# R7FA2L1AB register map
Vendor: Renesas Electronics Corporation; Series: RA2L1; File version: 1.60.00
CPU: CM23 r1p0, little endian, MPU, no FPU, VTOR, 2 interrupt priority bits, 32 interrupts
Registers are 8-bit, read-write, reset 0x0 unless marked. A register's access mark holds for its fields unless they carry their own. Offsets are from the block's base; [hi:lo] are bit positions; 'fields as' and 'values as' point back to an identical list.

## POEG — Port Output Enable Module for GPT
Base 0x40042000
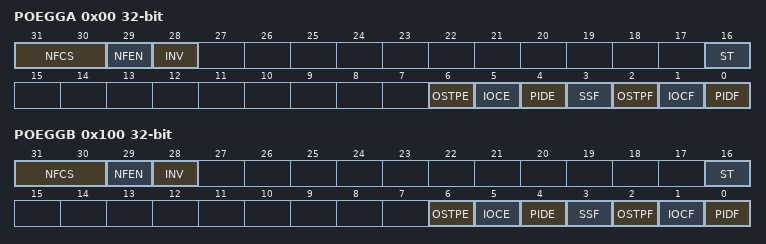
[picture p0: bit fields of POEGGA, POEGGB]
0x00 POEGGA 32-bit — POEG Group A Setting Register
  [31:30] NFCS — Noise Filter Clock Select
    0=Sample GTETRGn pin input level three times every PCLKB; 1=Sample GTETRGn pin input level three times every PCLKB/8; 2=Sample GTETRGn pin input level three times every PCLKB/32; 3=Sample GTETRGn pin input level three times every PCLKB/128
  [29] NFEN — Noise Filter Enable
    0=Disable noise filtering; 1=Enable noise filtering
  [28] INV — GTETRGA Input Reverse
    0=Input GTETRGn as-is; 1=Input GTETRGn in reverse
  [16] ST ro — GTETRGA Input Status Flag
    0=GTETRGn input after filtering was 0; 1=GTETRGn input after filtering was 1
  [6] OSTPE — Oscillation Stop Detection Enable
    0=Disable output-disable requests from oscillation stop detection; 1=Enable output-disable requests from oscillation stop detection
  [5] IOCE — Enable for GPT Output-Disable Request
    0=Disable output-disable requests from GPT; 1=Enable output-disable requests from GPT
  [4] PIDE — Port Input Detection Enable
    0=Disable output-disable requests from the GTETRGn pins; 1=Enable output-disable requests from the GTETRGn pins
  [3] SSF — Software Stop Flag
    0=No output-disable request from software occurred; 1=Output-disable request from software occurred
  [2] OSTPF — Oscillation Stop Detection Flag
    0=No output-disable request from oscillation stop detection occurred; 1=Output-disable request from oscillation stop detection occurred
  [1] IOCF — Detection Flag for GPT Output-Disable Request
    0=No output-disable request from GPT occurred; 1=Output-disable request from GPT occurred
  [0] PIDF — Port Input Detection Flag
    0=No output-disable request from the GTETRGn pin occurred; 1=Output-disable request from the GTETRGn pin occurred
0x100 POEGGB 32-bit — POEG Group B Setting Register
  [31:30] NFCS — Noise Filter Clock Select
    values as POEGGA.NFCS
  [29] NFEN — Noise Filter Enable
    0=Disable noise filtering; 1=Enable noise filtering
  [28] INV — GTETRGB Input Reverse
    0=Input GTETRGn as-is; 1=Input GTETRGn in reverse
  [16] ST ro — GTETRGB Input Status Flag
    values as POEGGA.ST
  [6] OSTPE — Oscillation Stop Detection Enable
    values as POEGGA.OSTPE
  [5] IOCE — Enable for GPT Output-Disable Request
    values as POEGGA.IOCE
  [4] PIDE — Port Input Detection Enable
    values as POEGGA.PIDE
  [3] SSF — Software Stop Flag
    values as POEGGA.SSF
  [2] OSTPF — Oscillation Stop Detection Flag
    values as POEGGA.OSTPF
  [1] IOCF — Detection Flag for GPT Output-Disable Request
    values as POEGGA.IOCF
  [0] PIDF — Port Input Detection Flag
    values as POEGGA.PIDF

## WDT — Watchdog Timer
Base 0x40044200
0x00 WDTRR reset 0xFF — WDT Refresh Register
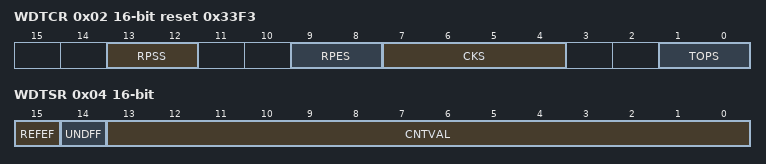
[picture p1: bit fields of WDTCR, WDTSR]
0x02 WDTCR 16-bit reset 0x33F3 — WDT Control Register
  [13:12] RPSS — Window Start Position Select
    0=25%; 1=50%; 2=75%; 3=100% (do not specify window start position)
  [9:8] RPES — Window End Position Select
    0=75%; 1=50%; 2=25%; 3=0% (do not specify window end position)
  [7:4] CKS — Clock Division Ratio Select
    1=PCLKB/4; 4=PCLKB/64; 15=PCLKB/128; 6=PCLKB/512; 7=PCLKB/2048; 8=PCLKB/8192; other=Others (Setting prohibited)
  [1:0] TOPS — Timeout Period Select
    0=1024 cycles (0x03FF); 1=4096 cycles (0x0FFF); 2=8192 cycles (0x1FFF); 3=16384 cycles (0x3FFF)
0x04 WDTSR 16-bit — WDT Status Register
  [15] REFEF — Refresh Error Flag
    0=No refresh error occurred; 1=Refresh error occurred
  [14] UNDFF — Underflow Flag
    0=No underflow occurred; 1=Underflow occurred
  [13:0] CNTVAL ro — Down-Counter Value
0x06 WDTRCR reset 0x80 — WDT Reset Control Register
  [7] RSTIRQS — WDT Behavior Selection
    0=Interrupt; 1=Reset
0x08 WDTCSTPR reset 0x80 — WDT Count Stop Control Register
  [7] SLCSTP — Sleep-Mode Count Stop Control Register
    0=Disable count stop; 1=Stop count on transition to Sleep mode
